VERSION ""

NS_ :

BS_:

BU_: ECU1 ECU2 ECU3

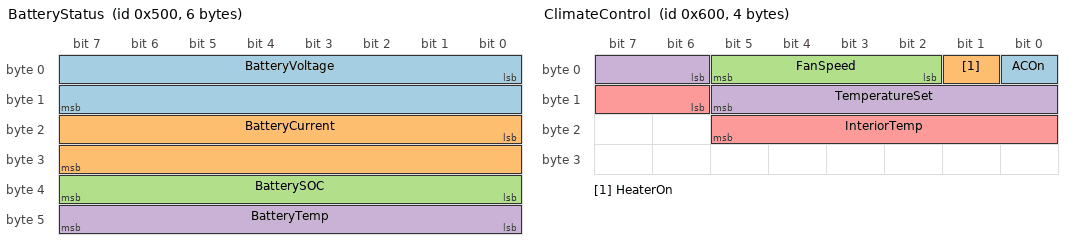
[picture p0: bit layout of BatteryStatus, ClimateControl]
BO_ 1280 BatteryStatus: 6 ECU3
 SG_ BatteryVoltage : 0|16@1+ (0.01,0) [0|655.35] "V" ECU2
 SG_ BatteryCurrent : 16|16@1+ (0.1,-3276.8) [-3276.8|3276.7] "A" ECU2
 SG_ BatterySOC : 32|8@1+ (0.5,0) [0|127.5] "%" ECU2
 SG_ BatteryTemp : 40|8@1+ (1,-40) [-40|215] "°C" ECU2

BO_ 1536 ClimateControl: 4 ECU3
 SG_ ACOn : 0|1@1+ (1,0) [0|1] "" ECU2
 SG_ HeaterOn : 1|1@1+ (1,0) [0|1] "" ECU2
 SG_ FanSpeed : 2|4@1+ (1,0) [0|15] "" ECU2
 SG_ TemperatureSet : 6|8@1+ (0.5,16) [16|30] "°C" ECU2
 SG_ InteriorTemp : 14|8@1+ (0.5,-40) [-40|87.5] "°C" ECU2

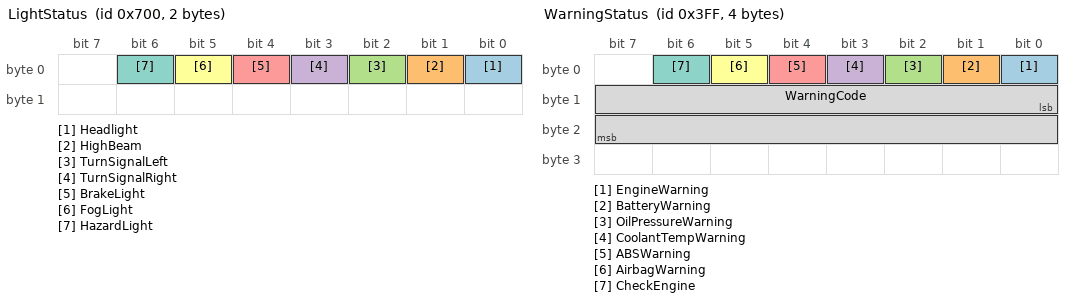
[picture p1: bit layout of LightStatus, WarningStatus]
BO_ 1792 LightStatus: 2 ECU3
 SG_ Headlight : 0|1@1+ (1,0) [0|1] "" ECU2
 SG_ HighBeam : 1|1@1+ (1,0) [0|1] "" ECU2
 SG_ TurnSignalLeft : 2|1@1+ (1,0) [0|1] "" ECU2
 SG_ TurnSignalRight : 3|1@1+ (1,0) [0|1] "" ECU2
 SG_ BrakeLight : 4|1@1+ (1,0) [0|1] "" ECU2
 SG_ FogLight : 5|1@1+ (1,0) [0|1] "" ECU2
 SG_ HazardLight : 6|1@1+ (1,0) [0|1] "" ECU2

VAL_ 1792 Headlight 0 "Off" 1 "On" ;
VAL_ 1792 HighBeam 0 "Off" 1 "On" ;
VAL_ 1792 TurnSignalLeft 0 "Off" 1 "On" ;
VAL_ 1792 TurnSignalRight 0 "Off" 1 "On" ;
VAL_ 1792 BrakeLight 0 "Off" 1 "On" ;
VAL_ 1792 FogLight 0 "Off" 1 "On" ;
VAL_ 1792 HazardLight 0 "Off" 1 "On" ;

BO_ 1023 WarningStatus: 4 ECU3
 SG_ EngineWarning : 0|1@1+ (1,0) [0|1] "" ECU2
 SG_ BatteryWarning : 1|1@1+ (1,0) [0|1] "" ECU2
 SG_ OilPressureWarning : 2|1@1+ (1,0) [0|1] "" ECU2
 SG_ CoolantTempWarning : 3|1@1+ (1,0) [0|1] "" ECU2
 SG_ ABSWarning : 4|1@1+ (1,0) [0|1] "" ECU2
 SG_ AirbagWarning : 5|1@1+ (1,0) [0|1] "" ECU2
 SG_ CheckEngine : 6|1@1+ (1,0) [0|1] "" ECU2
 SG_ WarningCode : 8|16@1+ (1,0) [0|65535] "" ECU2

VAL_ 1023 EngineWarning 0 "OK" 1 "Warning" ;
VAL_ 1023 BatteryWarning 0 "OK" 1 "Warning" ;
VAL_ 1023 OilPressureWarning 0 "OK" 1 "Warning" ;
VAL_ 1023 CoolantTempWarning 0 "OK" 1 "Warning" ;
VAL_ 1023 ABSWarning 0 "OK" 1 "Warning" ;
VAL_ 1023 AirbagWarning 0 "OK" 1 "Warning" ;
VAL_ 1023 CheckEngine 0 "OK" 1 "Warning" ;
